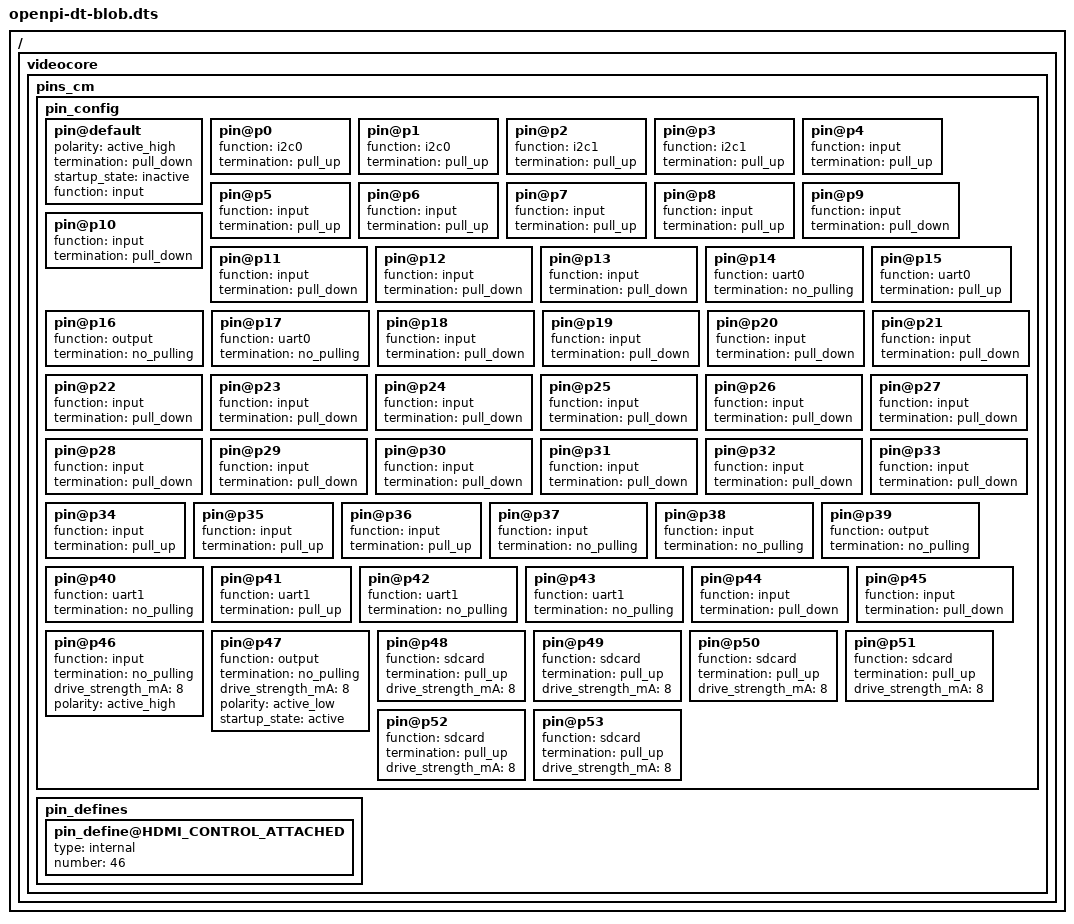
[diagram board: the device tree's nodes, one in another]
/dts-v1/;

/ {
  videocore {

    pins_cm {

      pin_config {

        pin@default {
          polarity = "active_high";
          termination = "pull_down";
          startup_state = "inactive";
          function = "input";
        }; // pin

        // BANK 0 - USER GPIO //
        pin@p0  { function = "i2c0";    termination = "pull_up";    }; // I2C 0 SDA
        pin@p1  { function = "i2c0";    termination = "pull_up";    }; // I2C 0 SCL
        pin@p2  { function = "i2c1";    termination = "pull_up";    }; // I2C 1 SDA
        pin@p3  { function = "i2c1";    termination = "pull_up";    }; // I2C 1 SCL
        pin@p4  { function = "input";   termination = "pull_up";    }; // DEFAULT STATE
        pin@p5  { function = "input";   termination = "pull_up";    }; // DEFAULT STATE
        pin@p6  { function = "input";   termination = "pull_up";    }; // DEFAULT STATE
        pin@p7  { function = "input";   termination = "pull_up";    }; // DEFAULT STATE
        pin@p8  { function = "input";   termination = "pull_up";    }; // DEFAULT STATE
        pin@p9  { function = "input";   termination = "pull_down";  }; // DEFAULT STATE
        pin@p10 { function = "input";   termination = "pull_down";  }; // DEFAULT STATE
        pin@p11 { function = "input";   termination = "pull_down";  }; // DEFAULT STATE
        pin@p12 { function = "input";   termination = "pull_down";  }; // DEFAULT STATE
        pin@p13 { function = "input";   termination = "pull_down";  }; // DEFAULT STATE
        pin@p14 { function = "uart0";   termination = "no_pulling"; }; // UART0 TX
        pin@p15 { function = "uart0";   termination = "pull_up";    }; // UART0 RX
        pin@p16 { function = "output";  termination = "no_pulling"; }; // AT Command Pin (active low)
        pin@p17 { function = "uart0";   termination = "no_pulling"; }; // UART0 RTS
        pin@p18 { function = "input";   termination = "pull_down";  }; // DEFAULT STATE
        pin@p19 { function = "input";   termination = "pull_down";  }; // DEFAULT STATE
        pin@p20 { function = "input";   termination = "pull_down";  }; // DEFAULT STATE
        pin@p21 { function = "input";   termination = "pull_down";  }; // DEFAULT STATE
        pin@p22 { function = "input";   termination = "pull_down";  }; // DEFAULT STATE
        pin@p23 { function = "input";   termination = "pull_down";  }; // DEFAULT STATE
        pin@p24 { function = "input";   termination = "pull_down";  }; // DEFAULT STATE
        pin@p25 { function = "input";   termination = "pull_down";  }; // DEFAULT STATE
        pin@p26 { function = "input";   termination = "pull_down";  }; // DEFAULT STATE
        pin@p27 { function = "input";   termination = "pull_down";  }; // DEFAULT STATE

        // BANK 1 - USER GPIO//
        pin@p28 { function = "input";   termination = "pull_down";  }; // DEFAULT STATE WAS INPUT NO PULL
        pin@p29 { function = "input";   termination = "pull_down";  }; // DEFAULT STATE WAS INPUT NO PULL
        pin@p30 { function = "input";   termination = "pull_down";  }; // DEFAULT STATE
        pin@p31 { function = "input";   termination = "pull_down";  }; // DEFAULT STATE
        pin@p32 { function = "input";   termination = "pull_down";  }; // DEFAULT STATE
        pin@p33 { function = "input";   termination = "pull_down";  }; // DEFAULT STATE IR_OUT
        pin@p34 { function = "input";   termination = "pull_up";    }; // DEFAULT STATE Button
        pin@p35 { function = "input";   termination = "pull_up";    }; // DEFAULT STATE IR_IN
        pin@p36 { function = "input";   termination = "pull_up";    }; // DEFAULT STATE SRF_RESET
        pin@p37 { function = "input";   termination = "no_pulling"; }; // HM10_RESET
        pin@p38 { function = "input";   termination = "no_pulling"; }; // HM10_LED
        pin@p39 { function = "output";  termination = "no_pulling"; }; // HM10_KEY
        pin@p40 { function = "uart1";   termination = "no_pulling"; }; // UART1 TX
        pin@p41 { function = "uart1";   termination = "pull_up";    }; // UART1 RX
        pin@p42 { function = "uart1";   termination = "no_pulling"; }; // UART1 RTS
        pin@p43 { function = "uart1";   termination = "no_pulling"; }; // UART1 CTS
        pin@p44 { function = "input";   termination = "pull_down";  }; // DEFAULT STATE WAS INPUT NO PULL
        pin@p45 { function = "input";   termination = "pull_down";  }; // DEFAULT STATE WAS INPUT NO PULL

        // BANK 2 - DON'T TOUCH UNLESS YOU KNOW WHAT YOU'RE DOING //
        pin@p46 { function = "input";   termination = "no_pulling"; drive_strength_mA = <8>; polarity = "active_high"; }; // HPD_N
        pin@p47 { function = "output";  termination = "no_pulling"; drive_strength_mA = <8>; polarity = "active_low"; startup_state = "active"; }; // STATUS LED / EMMC_DISABLE_N CONTROL
        pin@p48 { function = "sdcard";  termination = "pull_up";    drive_strength_mA = <8>; }; // SD CLK
        pin@p49 { function = "sdcard";  termination = "pull_up";    drive_strength_mA = <8>; }; // SD CMD
        pin@p50 { function = "sdcard";  termination = "pull_up";    drive_strength_mA = <8>; }; // SD D0
        pin@p51 { function = "sdcard";  termination = "pull_up";    drive_strength_mA = <8>; }; // SD D1
        pin@p52 { function = "sdcard";  termination = "pull_up";    drive_strength_mA = <8>; }; // SD D2
        pin@p53 { function = "sdcard";  termination = "pull_up";    drive_strength_mA = <8>; }; // SD D3

      }; // pin_config

      pin_defines {
        pin_define@HDMI_CONTROL_ATTACHED { type = "internal"; number = <46>; }; // HPD_N on GPIO46
      }; // pin_defines

    }; // pins_cm

  }; // videocore
};
